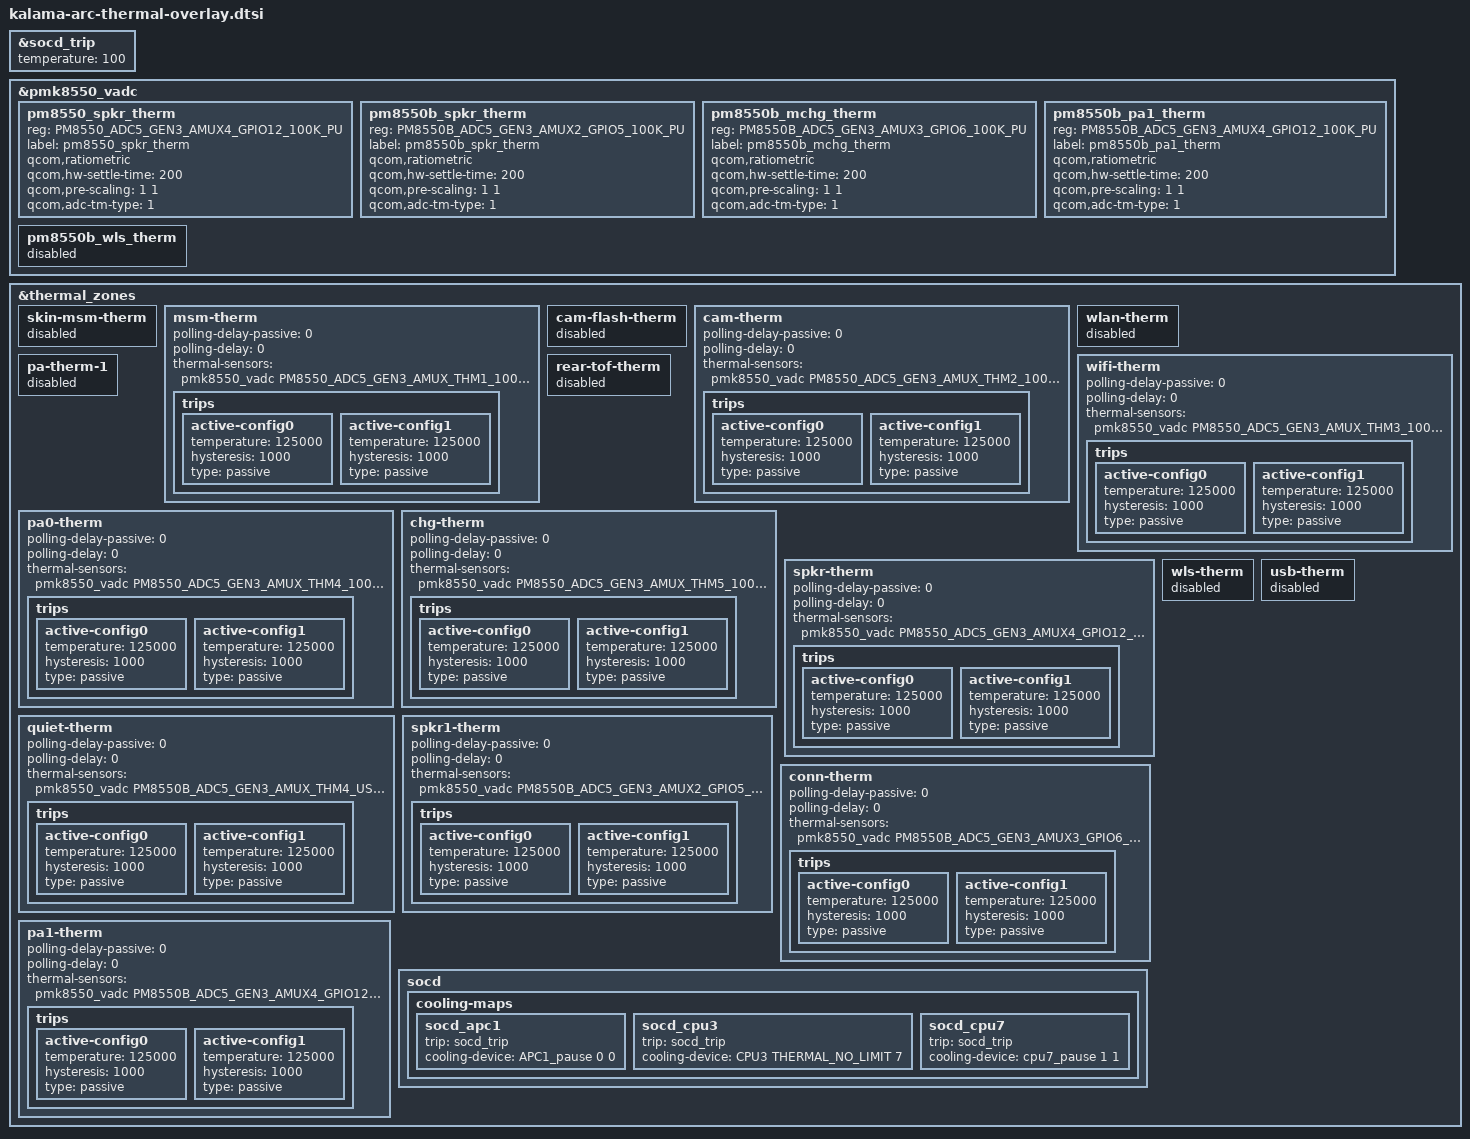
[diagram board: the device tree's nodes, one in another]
#include "moto_therm_sys_temp.dtsi"

/* Disable the BCL function of battery Soc due to competitor(e.g. OV, Sum)*/
&socd_trip {
    temperature = <100>;
};

/*
PM8550_ADC5_GEN3_AMUX_THM1_100K_PU : msm-therm (QC:skin-msm-therm in kalama-pmic-overlay.dtsi)
PM8550_ADC5_GEN3_AMUX_THM2_100K_PU : cam-therm (QC: cam-flash-therm in kalama-pmic-overlay.dtsi)
PM8550_ADC5_GEN3_AMUX_THM3_100K_PU : wifi-therm (QC: wlan-therm in kalama-pmic-overlay.dtsi)
PM8550_ADC5_GEN3_AMUX_THM4_100K_PU : pa0-therm (QC: pa-therm-1 in kalama-pmic-overlay.dtsi)
PM8550_ADC5_GEN3_AMUX_THM5_100K_PU : chg-therm (QC: rear-tof-therm in kalama-pmic-overlay.dtsi)
PM8550_ADC5_GEN3_AMUX4_GPIO12_100K_PU : spkr-therm (Added by Moto)
PM8550B_ADC5_GEN3_AMUX_THM4_USB_THERM_100K_PU : quiet-therm (QC: usb-therm in kalama-pmic-overlay.dtsi)
PM8550B_ADC5_GEN3_AMUX2_GPIO5_100K_PU : spkr1-therm (Added by Moto)
PM8550B_ADC5_GEN3_AMUX3_GPIO6_100K_PU : conn-therm (Added by Moto)
PM8550B_ADC5_GEN3_AMUX4_GPIO12_100K_PU : pa1-therm (Added by Moto)
PM8550B_ADC5_GEN3_AMUX_THM6_GPIO10_100K_PU : disabled (QC: wls-therm in kalama-pmic-overlay.dtsi)
*/

&pmk8550_vadc {
	pm8550_spkr_therm {
		reg = <PM8550_ADC5_GEN3_AMUX4_GPIO12_100K_PU>;
		label = "pm8550_spkr_therm";
		qcom,ratiometric;
		qcom,hw-settle-time = <200>;
		qcom,pre-scaling = <1 1>;
		qcom,adc-tm-type = <1>;
	};

	pm8550b_spkr_therm {
		reg = <PM8550B_ADC5_GEN3_AMUX2_GPIO5_100K_PU>;
		label = "pm8550b_spkr_therm";
		qcom,ratiometric;
		qcom,hw-settle-time = <200>;
		qcom,pre-scaling = <1 1>;
		qcom,adc-tm-type = <1>;
	};

	pm8550b_mchg_therm {
		reg = <PM8550B_ADC5_GEN3_AMUX3_GPIO6_100K_PU>;
		label = "pm8550b_mchg_therm";
		qcom,ratiometric;
		qcom,hw-settle-time = <200>;
		qcom,pre-scaling = <1 1>;
		qcom,adc-tm-type = <1>;
	};

	pm8550b_pa1_therm {
		reg = <PM8550B_ADC5_GEN3_AMUX4_GPIO12_100K_PU>;
		label = "pm8550b_pa1_therm";
		qcom,ratiometric;
		qcom,hw-settle-time = <200>;
		qcom,pre-scaling = <1 1>;
		qcom,adc-tm-type = <1>;
	};

	pm8550b_wls_therm {
		status = "disabled";
	};
};

&thermal_zones {
	skin-msm-therm {
		status = "disabled";
	};
	msm-therm {
		polling-delay-passive = <0>;
		polling-delay = <0>;
		thermal-sensors = <&pmk8550_vadc PM8550_ADC5_GEN3_AMUX_THM1_100K_PU>;
		trips {
			active-config0 {
				temperature = <125000>;
				hysteresis = <1000>;
				type = "passive";
			};

			active-config1 {
				temperature = <125000>;
				hysteresis = <1000>;
				type = "passive";
			};
		};
	};

	cam-flash-therm {
		status = "disabled";
	};
	cam-therm {
		polling-delay-passive = <0>;
		polling-delay = <0>;
		thermal-sensors = <&pmk8550_vadc PM8550_ADC5_GEN3_AMUX_THM2_100K_PU>;
		trips {
			active-config0 {
				temperature = <125000>;
				hysteresis = <1000>;
				type = "passive";
			};

			active-config1 {
				temperature = <125000>;
				hysteresis = <1000>;
				type = "passive";
			};
		};
	};

	wlan-therm {
		status = "disabled";
	};
	wifi-therm {
		polling-delay-passive = <0>;
		polling-delay = <0>;
		thermal-sensors = <&pmk8550_vadc PM8550_ADC5_GEN3_AMUX_THM3_100K_PU>;
		trips {
			active-config0 {
				temperature = <125000>;
				hysteresis = <1000>;
				type = "passive";
			};

			active-config1 {
				temperature = <125000>;
				hysteresis = <1000>;
				type = "passive";
			};
		};
	};

	pa-therm-1 {
		status = "disabled";
	};
	pa0-therm {
		polling-delay-passive = <0>;
		polling-delay = <0>;
		thermal-sensors = <&pmk8550_vadc PM8550_ADC5_GEN3_AMUX_THM4_100K_PU>;
		trips {
			active-config0 {
				temperature = <125000>;
				hysteresis = <1000>;
				type = "passive";
			};

			active-config1 {
				temperature = <125000>;
				hysteresis = <1000>;
				type = "passive";
			};
		};
	};

	rear-tof-therm {
		status = "disabled";
	};
	chg-therm {
		polling-delay-passive = <0>;
		polling-delay = <0>;
		thermal-sensors = <&pmk8550_vadc PM8550_ADC5_GEN3_AMUX_THM5_100K_PU>;
		trips {
			active-config0 {
				temperature = <125000>;
				hysteresis = <1000>;
				type = "passive";
			};

			active-config1 {
				temperature = <125000>;
				hysteresis = <1000>;
				type = "passive";
			};
		};
	};

	spkr-therm {
		polling-delay-passive = <0>;
		polling-delay = <0>;
		thermal-sensors = <&pmk8550_vadc PM8550_ADC5_GEN3_AMUX4_GPIO12_100K_PU>;
		trips {
			active-config0 {
				temperature = <125000>;
				hysteresis = <1000>;
				type = "passive";
			};

			active-config1 {
				temperature = <125000>;
				hysteresis = <1000>;
				type = "passive";
			};
		};
	};

	wls-therm {
		status = "disabled";
	};

	usb-therm {
		status = "disabled";
	};
	quiet-therm {
		polling-delay-passive = <0>;
		polling-delay = <0>;
		thermal-sensors = <&pmk8550_vadc PM8550B_ADC5_GEN3_AMUX_THM4_USB_THERM_100K_PU>;
		trips {
			active-config0 {
				temperature = <125000>;
				hysteresis = <1000>;
				type = "passive";
			};

			active-config1 {
				temperature = <125000>;
				hysteresis = <1000>;
				type = "passive";
			};
		};
	};

	spkr1-therm {
		polling-delay-passive = <0>;
		polling-delay = <0>;
		thermal-sensors = <&pmk8550_vadc PM8550B_ADC5_GEN3_AMUX2_GPIO5_100K_PU>;
		trips {
			active-config0 {
				temperature = <125000>;
				hysteresis = <1000>;
				type = "passive";
			};

			active-config1 {
				temperature = <125000>;
				hysteresis = <1000>;
				type = "passive";
			};
		};
	};

	conn-therm {
		polling-delay-passive = <0>;
		polling-delay = <0>;
		thermal-sensors = <&pmk8550_vadc PM8550B_ADC5_GEN3_AMUX3_GPIO6_100K_PU>;
		trips {
			active-config0 {
				temperature = <125000>;
				hysteresis = <1000>;
				type = "passive";
			};

			active-config1 {
				temperature = <125000>;
				hysteresis = <1000>;
				type = "passive";
			};
		};
	};

	pa1-therm {
		polling-delay-passive = <0>;
		polling-delay = <0>;
		thermal-sensors = <&pmk8550_vadc PM8550B_ADC5_GEN3_AMUX4_GPIO12_100K_PU>;
		trips {
			active-config0 {
				temperature = <125000>;
				hysteresis = <1000>;
				type = "passive";
			};

			active-config1 {
				temperature = <125000>;
				hysteresis = <1000>;
				type = "passive";
			};
		};
	};

	socd {
		cooling-maps {
			socd_apc1 {
				trip = <&socd_trip>;
				cooling-device = <&APC1_pause 0 0>;
			};
			socd_cpu3 {
				trip = <&socd_trip>;
				cooling-device = <&CPU3 THERMAL_NO_LIMIT 7>;
			};
			socd_cpu7 {
				trip = <&socd_trip>;
				cooling-device = <&cpu7_pause 1 1>;
			};
		};
	};
};
